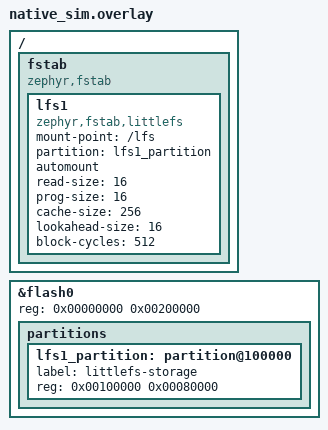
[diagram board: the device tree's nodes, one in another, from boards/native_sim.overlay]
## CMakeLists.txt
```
cmake_minimum_required(VERSION 3.20.0)
find_package(Zephyr REQUIRED HINTS $ENV{ZEPHYR_BASE})
project(test_shell)

target_sources(app PRIVATE
    src/main.c
    ${CMAKE_CURRENT_SOURCE_DIR}/../../../src/shell/shell_shg.c
    ${CMAKE_CURRENT_SOURCE_DIR}/../../../src/shell/shell_fs.c
    ${CMAKE_CURRENT_SOURCE_DIR}/../../../src/system_mgr/system_mgr.c
    ${CMAKE_CURRENT_SOURCE_DIR}/../../../src/storage_mgr/storage_mgr.c
)

target_include_directories(app PRIVATE
    ${CMAKE_CURRENT_SOURCE_DIR}/../../../src/
)
```

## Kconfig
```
source "Kconfig.zephyr"

config SHG_SHELL_PRODUCTION
	bool "Enable production shell commands"
	default y

config SYSTEM_MGR_LOG_LEVEL
	int "System Manager log level"
	default 3

config STORAGE_MGR_LOG_LEVEL
	int "Storage Manager log level"
	default 3
```

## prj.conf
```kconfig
# Test configuration for shell commands on native_sim
CONFIG_ZTEST=y

CONFIG_FLASH=y
CONFIG_FLASH_MAP=y
CONFIG_FLASH_PAGE_LAYOUT=y

CONFIG_FILE_SYSTEM=y
CONFIG_FILE_SYSTEM_LITTLEFS=y

CONFIG_NVS=y

CONFIG_LOG=y
CONFIG_LOG_MODE_DEFERRED=y

CONFIG_HEAP_MEM_POOL_SIZE=16384
CONFIG_MAIN_STACK_SIZE=4096

# Shell with dummy backend for test capture
CONFIG_SHELL=y
CONFIG_SHELL_BACKEND_SERIAL=n
CONFIG_SHELL_BACKEND_DUMMY=y
CONFIG_SHELL_BACKEND_DUMMY_BUF_SIZE=4096
CONFIG_SHELL_LOG_BACKEND=n

# Application shell features
CONFIG_SHG_SHELL_PRODUCTION=y
```

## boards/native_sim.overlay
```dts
/ {
	fstab {
		compatible = "zephyr,fstab";
		lfs1: lfs1 {
			compatible = "zephyr,fstab,littlefs";
			mount-point = "/lfs";
			partition = <&lfs1_partition>;
			automount;
			read-size = <16>;
			prog-size = <16>;
			cache-size = <256>;
			lookahead-size = <16>;
			block-cycles = <512>;
		};
	};
};

&flash0 {
	reg = <0x00000000 0x00200000>;

	partitions {
		lfs1_partition: partition@100000 {
			label = "littlefs-storage";
			reg = <0x00100000 0x00080000>;
		};
	};
};
```

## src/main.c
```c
/* =========================================================================
 * tests/unit/test_shell/src/main.c — Shell command unit tests
 * ========================================================================= */
#include <zephyr/ztest.h>
#include <zephyr/shell/shell.h>
#include <zephyr/shell/shell_dummy.h>
#include <string.h>

#include "storage_mgr/storage_mgr.h"
#include "system_mgr/system_mgr.h"

static const struct shell *sh;

static void *shell_test_setup(void)
{
	int ret;

	ret = storage_mgr_init();
	zassert_true(ret == 0 || ret == -EALREADY,
		     "storage_mgr_init failed: %d", ret);

	ret = system_mgr_init();
	zassert_true(ret == 0 || ret == -EALREADY,
		     "system_mgr_init failed: %d", ret);

	sh = shell_backend_dummy_get_ptr();
	zassert_not_null(sh, "Failed to get dummy shell backend");

	/* Wait for shell backend to become active */
	while (!shell_ready(sh)) {
		k_msleep(10);
	}

	return NULL;
}

ZTEST_SUITE(shell_tests, NULL, shell_test_setup, NULL, NULL, NULL);

ZTEST(shell_tests, test_shell_shg_info)
{
	int ret;
	size_t size;

	shell_backend_dummy_clear_output(sh);
	ret = shell_execute_cmd(sh, "shg info");
	zassert_ok(ret, "shg info failed: %d", ret);

	const char *output = shell_backend_dummy_get_output(sh, &size);

	zassert_true(size > 0, "No output from shg info");
	zassert_not_null(strstr(output, "Firmware"),
			 "Version info not found in output:\n%s", output);
}

ZTEST(shell_tests, test_shell_fs_ls)
{
	int ret;

	/* Write a test file so it shows up in listing */
	ret = storage_mgr_file_write("/lfs/ls_test.txt", "data", 4);
	zassert_equal(ret, 0, "file write failed: %d", ret);

	size_t size;

	shell_backend_dummy_clear_output(sh);
	ret = shell_execute_cmd(sh, "fs ls /lfs");
	zassert_ok(ret, "fs ls failed: %d", ret);

	const char *output = shell_backend_dummy_get_output(sh, &size);

	zassert_true(size > 0, "No output from fs ls");
	zassert_not_null(strstr(output, "ls_test.txt"),
			 "ls_test.txt not found in output:\n%s", output);
}

ZTEST(shell_tests, test_shell_fs_cat)
{
	int ret;
	const char *content = "hello from test";

	ret = storage_mgr_file_write("/lfs/cat_test.txt", content,
				     strlen(content));
	zassert_equal(ret, 0, "file write failed: %d", ret);

	size_t size;

	shell_backend_dummy_clear_output(sh);
	ret = shell_execute_cmd(sh, "fs cat /lfs/cat_test.txt");
	zassert_ok(ret, "fs cat failed: %d", ret);

	const char *output = shell_backend_dummy_get_output(sh, &size);

	zassert_true(size > 0, "No output from fs cat");
	zassert_not_null(strstr(output, "hello from test"),
			 "File content not found in output:\n%s", output);
}
```
